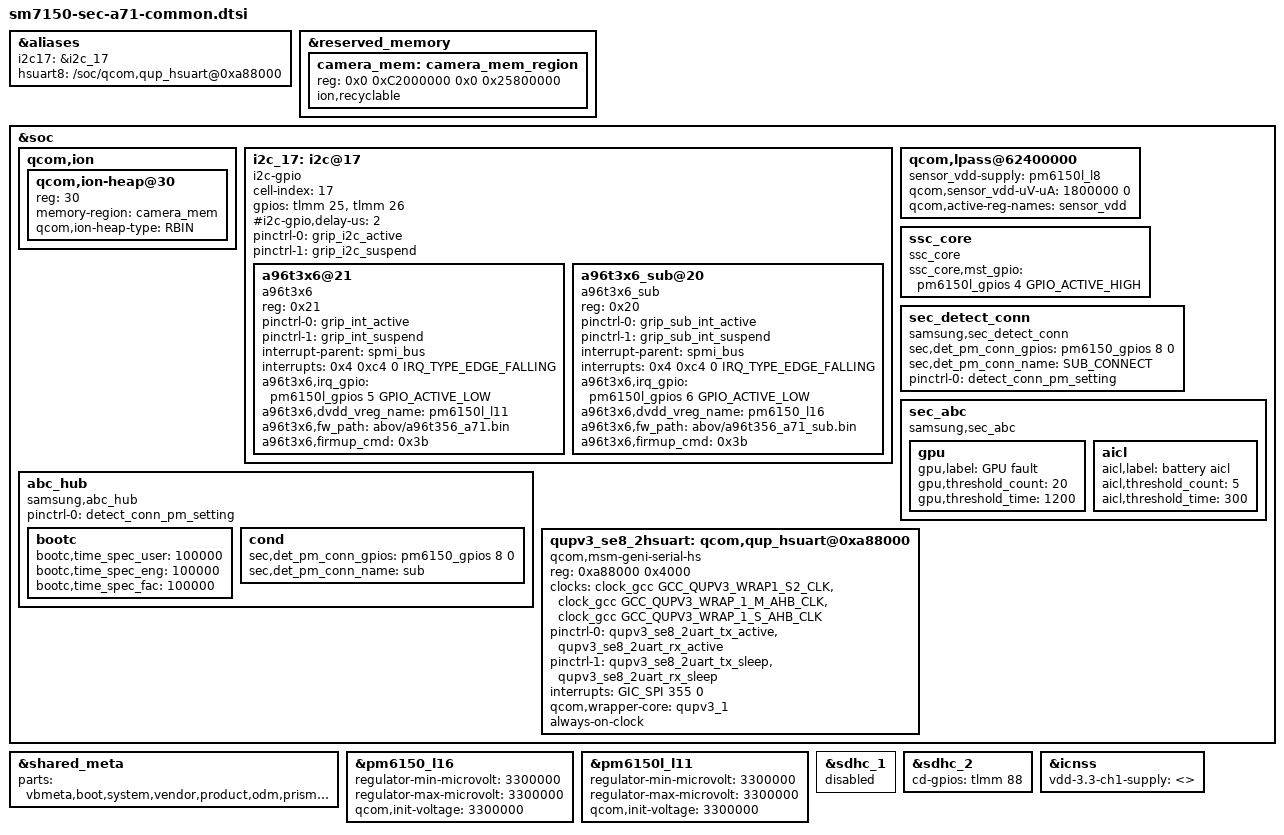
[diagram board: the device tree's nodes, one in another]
/* Copyright (c) 2019, The Linux Foundation. All rights reserved.
 *
 * This program is free software; you can redistribute it and/or modify
 * it under the terms of the GNU General Public License version 2 and
 * only version 2 as published by the Free Software Foundation.
 *
 * This program is distributed in the hope that it will be useful,
 * but WITHOUT ANY WARRANTY; without even the implied warranty of
 * MERCHANTABILITY or FITNESS FOR A PARTICULAR PURPOSE.  See the
 * GNU General Public License for more details.
 */


#include <dt-bindings/clock/qcom,gcc-sdmmagpie.h>
#include "../drivers/sm7150-sec-a71-audio.dtsi"
#include "sm7150-sec-a71-input-common.dtsi"
#include "sm7150-sec-a71-pinctrl-common.dtsi"
#include "../drivers/sm7150-sec-a71-mst-r00.dtsi"

&aliases {
	i2c17 = &i2c_17;
	hsuart8 = "/soc/qcom,qup_hsuart@0xa88000";
};

&reserved_memory {
	camera_mem: camera_mem_region {
		reg = <0x0 0xC2000000 0x0 0x25800000>;
		ion,recyclable;
	};
};

&soc {
	qcom,ion {
		qcom,ion-heap@30 { /* CAMERA HEAP  */
			reg = <30>;
			memory-region = <&camera_mem>;
			qcom,ion-heap-type = "RBIN";
		};
	};
};

&soc {
	i2c_17: i2c@17 { /* SW I2C */
		status = "ok";

		cell-index = <17>;
		compatible = "i2c-gpio";
		gpios = <&tlmm 25 0 /* sda */
			 &tlmm 26 0 /* scl */
		>;
		#i2c-gpio,delay-us = <2>;
		#address-cells = <1>;
		#size-cells = <0>;
		pinctrl-names = "default", "sleep";
		pinctrl-0 = <&grip_i2c_active>;
		pinctrl-1 = <&grip_i2c_suspend>;

		a96t3x6@21 {
			compatible = "a96t3x6";
			reg = <0x21>;
			pinctrl-names = "default";
			pinctrl-0 = <&grip_int_active>;
			pinctrl-1 = <&grip_int_suspend>;

			interrupt-parent = <&spmi_bus>;
			interrupts = <0x4 0xc4 0 IRQ_TYPE_EDGE_FALLING>;

			a96t3x6,irq_gpio = <&pm6150l_gpios 5 GPIO_ACTIVE_LOW>;
			a96t3x6,dvdd_vreg_name = "pm6150l_l11";
			a96t3x6,fw_path = "abov/a96t356_a71.bin";
			a96t3x6,firmup_cmd = <0x3b>;
		};

		a96t3x6_sub@20 {
			compatible = "a96t3x6_sub";
			reg = <0x20>;
			pinctrl-names = "default";
			pinctrl-0 = <&grip_sub_int_active>;
			pinctrl-1 = <&grip_sub_int_suspend>;

			interrupt-parent = <&spmi_bus>;
			interrupts = <0x4 0xc4 0 IRQ_TYPE_EDGE_FALLING>;

			a96t3x6,irq_gpio = <&pm6150l_gpios 6 GPIO_ACTIVE_LOW>;
			a96t3x6,dvdd_vreg_name = "pm6150_l16";
			a96t3x6,fw_path = "abov/a96t356_a71_sub.bin";
			a96t3x6,firmup_cmd = <0x3b>;
		};
	};

	/* Sensor */
       	qcom,lpass@62400000 {
		sensor_vdd-supply = <&pm6150l_l8>;
		qcom,sensor_vdd-uV-uA = <1800000 0>;
		qcom,active-reg-names = "sensor_vdd";
       	};

	ssc_core {
		status = "okay";
		compatible = "ssc_core";
		ssc_core,mst_gpio = <&pm6150l_gpios 4 GPIO_ACTIVE_HIGH>;
	};

	sec_detect_conn {
		compatible = "samsung,sec_detect_conn";

		sec,det_pm_conn_gpios = <&pm6150_gpios 8 0>; /* SUB_CONNECT */
		sec,det_pm_conn_name = "SUB_CONNECT";


		pinctrl-names = "det_pm_connect";
		pinctrl-0 = <&detect_conn_pm_setting>;
	};
	
	sec_abc {
				compatible = "samsung,sec_abc";
				status = "okay";

				gpu {
					gpu,label="GPU fault";
					gpu,threshold_count=<20>;
					gpu,threshold_time=<1200>;
				};
				aicl {
					aicl,label="battery aicl";
					aicl,threshold_count=<5>;
					aicl,threshold_time=<300>;
				};
			};

	abc_hub {
		compatible = "samsung,abc_hub";
		status = "okay";

		pinctrl-names = "det_pm_connect";
		pinctrl-0 = <&detect_conn_pm_setting>;

		bootc {
			bootc,time_spec_user = <100000>; /* user binary user build */
			bootc,time_spec_eng = <100000>; /* user binary eng build */
			bootc,time_spec_fac = <100000>; /* factory binary */
		};

		cond {
			sec,det_pm_conn_gpios = <&pm6150_gpios 8 0>; /* SUB_CONNECT */
			sec,det_pm_conn_name = "sub";
		};
	};
	
	qupv3_se8_2hsuart: qcom,qup_hsuart@0xa88000 {
		compatible = "qcom,msm-geni-serial-hs", "qcom,msm-geni-uart";
		reg = <0xa88000 0x4000>;
		reg-names = "se_phys";
		clock-names = "se-clk", "m-ahb", "s-ahb";
		clocks = <&clock_gcc GCC_QUPV3_WRAP1_S2_CLK>,
			<&clock_gcc GCC_QUPV3_WRAP_1_M_AHB_CLK>,
			<&clock_gcc GCC_QUPV3_WRAP_1_S_AHB_CLK>;
		pinctrl-names = "default", "sleep";
		pinctrl-0 = <&qupv3_se8_2uart_tx_active>,<&qupv3_se8_2uart_rx_active>;
		pinctrl-1 = <&qupv3_se8_2uart_tx_sleep>,<&qupv3_se8_2uart_rx_sleep>;
		interrupts = <GIC_SPI 355 0>;
		qcom,wrapper-core = <&qupv3_1>;
		status = "ok";
		always-on-clock;
	};
};

&shared_meta {
	status = "okay";
	parts = "vbmeta,boot,system,vendor,product,odm,prism,optics,vbmeta_samsung,recovery,dtbo,abl,xbl,tz,hyp";
};

/* Grip Sensor */
&pm6150_l16 {
	regulator-min-microvolt = <3300000>;
	regulator-max-microvolt = <3300000>;
	qcom,init-voltage = <3300000>;
};

&pm6150l_l11 {
	regulator-min-microvolt = <3300000>;
	regulator-max-microvolt = <3300000>;
	qcom,init-voltage = <3300000>;
};

/* not use eMMC */
&sdhc_1 {
	status = "disabled";
};
/* not use SDcard */
&sdhc_2 {
	cd-gpios = <&tlmm 88 0x0>;
};

&icnss {
	vdd-3.3-ch1-supply = <>;
};

